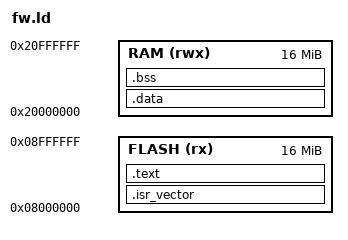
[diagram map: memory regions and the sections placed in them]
MEMORY { FLASH (rx) : ORIGIN = 0x08000000, LENGTH = 16M
         RAM (rwx) : ORIGIN = 0x20000000, LENGTH = 16M }
ENTRY(Reset_Handler)
SECTIONS {
  .isr_vector : { KEEP(*(.isr_vector)) } > FLASH
  .text : { *(.text*) *(.rodata*) *(.ARM.exidx*) . = ALIGN(4); _etext = .; } > FLASH
  .data : AT(_etext) { _sdata = .; *(.data*) . = ALIGN(4); _edata = .; } > RAM
  .bss : { _sbss = .; *(.bss*) *(COMMON) . = ALIGN(4); _ebss = .; } > RAM
  _estack = ORIGIN(RAM) + LENGTH(RAM);
}
